VERSION ""

NS_ :

BS_:

BU_: BCM LSN WBP ACT

BO_ 258 LIGHT_CMD: 7 BCM
 SG_ Led_B0_0 : 0|1@1+ (1,0) [0|1] "" LSN
 SG_ Led_B0_1 : 1|1@1+ (1,0) [0|1] "" LSN
 SG_ Led_B0_3 : 3|1@1+ (1,0) [0|1] "" LSN
 SG_ Led_B0_4 : 4|1@1+ (1,0) [0|1] "" LSN
 SG_ Led_B0_5 : 5|1@1+ (1,0) [0|1] "" LSN
 SG_ Led_B0_6 : 6|1@1+ (1,0) [0|1] "" LSN
 SG_ Led_B0_7 : 7|1@1+ (1,0) [0|1] "" LSN
 SG_ Led_B1_0 : 8|1@1+ (1,0) [0|1] "" LSN
 SG_ Led_B1_1 : 9|1@1+ (1,0) [0|1] "" LSN
 SG_ Led_B1_2 : 10|1@1+ (1,0) [0|1] "" LSN
 SG_ Led_B1_3 : 11|1@1+ (1,0) [0|1] "" LSN
 SG_ Led_B1_4 : 12|1@1+ (1,0) [0|1] "" LSN
 SG_ Led_B1_5 : 13|1@1+ (1,0) [0|1] "" LSN
 SG_ Led_B1_6 : 14|1@1+ (1,0) [0|1] "" LSN
 SG_ Led_B1_7 : 15|1@1+ (1,0) [0|1] "" LSN
 SG_ Led_B2_0 : 16|1@1+ (1,0) [0|1] "" LSN
 SG_ Led_B2_1 : 17|1@1+ (1,0) [0|1] "" LSN
 SG_ Led_B2_2 : 18|1@1+ (1,0) [0|1] "" LSN
 SG_ Led_B2_3 : 19|1@1+ (1,0) [0|1] "" LSN
 SG_ Led_B2_4 : 20|1@1+ (1,0) [0|1] "" LSN
 SG_ Led_B2_5 : 21|1@1+ (1,0) [0|1] "" LSN
 SG_ Led_B2_6 : 22|1@1+ (1,0) [0|1] "" LSN
 SG_ Led_B2_7 : 23|1@1+ (1,0) [0|1] "" LSN
 SG_ Led_B3_0 : 24|1@1+ (1,0) [0|1] "" LSN
 SG_ Led_B3_1 : 25|1@1+ (1,0) [0|1] "" LSN
 SG_ Led_B3_2 : 26|1@1+ (1,0) [0|1] "" LSN
 SG_ Led_B3_3 : 27|1@1+ (1,0) [0|1] "" LSN
 SG_ Led_B3_4 : 28|1@1+ (1,0) [0|1] "" LSN
 SG_ Led_B3_5 : 29|1@1+ (1,0) [0|1] "" LSN
 SG_ Led_B3_6 : 30|1@1+ (1,0) [0|1] "" LSN
 SG_ Led_B3_7 : 31|1@1+ (1,0) [0|1] "" LSN
 SG_ Led_B4_0 : 32|1@1+ (1,0) [0|1] "" LSN
 SG_ Led_B4_1 : 33|1@1+ (1,0) [0|1] "" LSN
 SG_ Led_B4_2 : 34|1@1+ (1,0) [0|1] "" LSN
 SG_ Led_B4_3 : 35|1@1+ (1,0) [0|1] "" LSN
 SG_ Led_B4_4 : 36|1@1+ (1,0) [0|1] "" LSN
 SG_ Led_B4_5 : 37|1@1+ (1,0) [0|1] "" LSN
 SG_ Led_B4_6 : 38|1@1+ (1,0) [0|1] "" LSN
 SG_ Led_B4_7 : 39|1@1+ (1,0) [0|1] "" LSN
 SG_ Seq_Counter : 40|4@1+ (1,0) [0|15] "" LSN
 SG_ CRC_Checksum : 48|8@1+ (1,0) [0|255] "" LSN
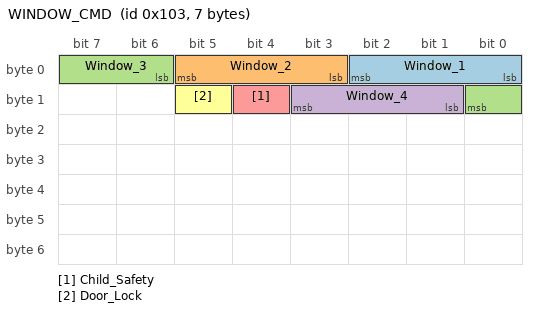
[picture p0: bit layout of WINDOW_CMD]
BO_ 259 WINDOW_CMD: 7 BCM
 SG_ Window_1 : 0|3@1+ (1,0) [0|4] "" ACT
 SG_ Window_2 : 3|3@1+ (1,0) [0|4] "" ACT
 SG_ Window_3 : 6|3@1+ (1,0) [0|4] "" ACT
 SG_ Window_4 : 9|3@1+ (1,0) [0|4] "" ACT
 SG_ Child_Safety : 12|1@1+ (1,0) [0|1] "" ACT
 SG_ Door_Lock : 13|1@1+ (1,0) [0|1] "" ACT
